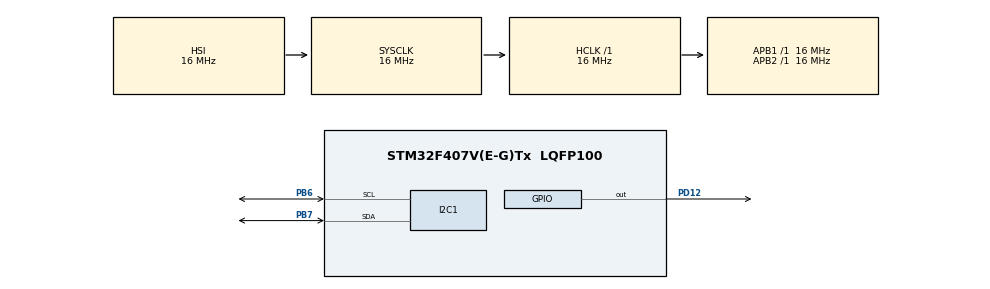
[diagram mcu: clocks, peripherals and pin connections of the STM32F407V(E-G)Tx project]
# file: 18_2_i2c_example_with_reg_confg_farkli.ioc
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I2C1.DutyCycle=I2C_DUTYCYCLE_16_9
I2C1.I2C_Mode=I2C_Fast
Mcu.Family=STM32F4
Mcu.Name=STM32F407V(E-G)Tx
Mcu.Package=LQFP100
NVIC.PriorityGroup=NVIC_PRIORITYGROUP_4
PA13.Mode=Serial_Wire
PA13.Signal=SYS_JTMS-SWDIO
PA14.Mode=Serial_Wire
PA14.Signal=SYS_JTCK-SWCLK
PB6.Mode=I2C
PB6.Signal=I2C1_SCL
PB7.Mode=I2C
PB7.Signal=I2C1_SDA
PD12.Signal=GPIO_Output
ProjectManager.HeapSize=0x200
ProjectManager.StackSize=0x400
ProjectManager.TargetToolchain=MDK-ARM V5
RCC.AHBFreq_Value=16000000
RCC.APB1Freq_Value=16000000
RCC.APB2Freq_Value=16000000
RCC.CortexFreq_Value=16000000
RCC.HSE_VALUE=25000000
RCC.HSI_VALUE=16000000
RCC.LSE_VALUE=32768
RCC.SYSCLKFreq_VALUE=16000000
RCC.VCOOutputFreq_Value=192000000
board=18_2_i2c_example_with_reg_confg_farkli

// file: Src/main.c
/**
  ******************************************************************************
  * File Name          : main.c
  * Description        : Main program body
  ******************************************************************************
  ** This notice applies to any and all portions of this file
  * that are not between comment pairs USER CODE BEGIN and
  * USER CODE END. Other portions of this file, whether
  * inserted by the user or by software development tools
  * are owned by their respective copyright owners.
  *
  * COPYRIGHT(c) 2018 STMicroelectronics
  *
  * Redistribution and use in source and binary forms, with or without modification,
  * are permitted provided that the following conditions are met:
  *   1. Redistributions of source code must retain the above copyright notice,
  *      this list of conditions and the following disclaimer.
  *   2. Redistributions in binary form must reproduce the above copyright notice,
  *      this list of conditions and the following disclaimer in the documentation
  *      and/or other materials provided with the distribution.
  *   3. Neither the name of STMicroelectronics nor the names of its contributors
  *      may be used to endorse or promote products derived from this software
  *      without specific prior written permission.
  *
  * THIS SOFTWARE IS PROVIDED BY THE COPYRIGHT HOLDERS AND CONTRIBUTORS "AS IS"
  * AND ANY EXPRESS OR IMPLIED WARRANTIES, INCLUDING, BUT NOT LIMITED TO, THE
  * IMPLIED WARRANTIES OF MERCHANTABILITY AND FITNESS FOR A PARTICULAR PURPOSE ARE
  * DISCLAIMED. IN NO EVENT SHALL THE COPYRIGHT HOLDER OR CONTRIBUTORS BE LIABLE
  * FOR ANY DIRECT, INDIRECT, INCIDENTAL, SPECIAL, EXEMPLARY, OR CONSEQUENTIAL
  * DAMAGES (INCLUDING, BUT NOT LIMITED TO, PROCUREMENT OF SUBSTITUTE GOODS OR
  * SERVICES; LOSS OF USE, DATA, OR PROFITS; OR BUSINESS INTERRUPTION) HOWEVER
  * CAUSED AND ON ANY THEORY OF LIABILITY, WHETHER IN CONTRACT, STRICT LIABILITY,
  * OR TORT (INCLUDING NEGLIGENCE OR OTHERWISE) ARISING IN ANY WAY OUT OF THE USE
  * OF THIS SOFTWARE, EVEN IF ADVISED OF THE POSSIBILITY OF SUCH DAMAGE.
  *
  ******************************************************************************
  */
#include "main.h"
#include "stm32f4xx_hal.h"
 #define mpu6050address 0xD0
 #define REG_CHIP_ID_1  0x75   // who_am_i
 #define REG_CHIP_ID_2  0x1C   // acce_config
 #define PWR_MGMT_1     0x6B
 #define ACCEL_XOUT_H   0x3B

I2C_HandleTypeDef hi2c1;

/* USER CODE BEGIN PV */
/* Private variables ---------------------------------------------------------*/

/* USER CODE END PV */

void SystemClock_Config(void);
static void MX_GPIO_Init(void);
static void MX_I2C1_Init(void);

/* USER CODE BEGIN PFP */
/* Private function prototypes -----------------------------------------------*/

/* USER CODE END PFP */
uint8_t i2cTx[3];
uint8_t i2cRx[10];
uint8_t x,y,z;

int main(void)
{

  /* MCU Configuration----------------------------------------------------------*/

  /* Reset of all peripherals, Initializes the Flash interface and the Systick. */
  HAL_Init();

  /* Configure the system clock */
  SystemClock_Config();

  /* Initialize all configured peripherals */
  MX_GPIO_Init();
  MX_I2C1_Init();

  /* USER CODE BEGIN 2 */
		if(HAL_I2C_IsDeviceReady(&hi2c1,0xD0,2,100)==HAL_OK) // cihazi test ediyoruz çalisiyormu diye.
		{
			HAL_GPIO_TogglePin(GPIOD,GPIO_PIN_12);
		}

		HAL_I2C_Mem_Read(&hi2c1,mpu6050address,REG_CHIP_ID_1,1,i2cRx,1,100); // çalisti yazmayi deneyelim :
		HAL_Delay(20);

		i2cTx[0]=0x00;
		HAL_I2C_Mem_Write(&hi2c1,mpu6050address,PWR_MGMT_1,1,&i2cTx[0],1,100);
		HAL_Delay(20);
	 	HAL_I2C_Mem_Read(&hi2c1,mpu6050address,PWR_MGMT_1,1,&i2cRx[1],1,100);
		HAL_Delay(20);

		i2cTx[1]=0x08;
	  HAL_I2C_Mem_Write(&hi2c1,mpu6050address,REG_CHIP_ID_2,1,&i2cTx[1],1,100);
		HAL_Delay(20);
	 	HAL_I2C_Mem_Read(&hi2c1,mpu6050address,REG_CHIP_ID_2,1,&i2cRx[2],1,100);
    HAL_Delay(20);

  /* USER CODE END 2 */

  /* Infinite loop */
  while (1)
  {
		HAL_I2C_Mem_Read(&hi2c1,mpu6050address,ACCEL_XOUT_H,1,&i2cRx[3],6,100);
    HAL_Delay(300);
  }

}

/** System Clock Configuration
*/
void SystemClock_Config(void)
{

  RCC_OscInitTypeDef RCC_OscInitStruct;
  RCC_ClkInitTypeDef RCC_ClkInitStruct;

    /**Configure the main internal regulator output voltage
    */
  __HAL_RCC_PWR_CLK_ENABLE();

  __HAL_PWR_VOLTAGESCALING_CONFIG(PWR_REGULATOR_VOLTAGE_SCALE1);

    /**Initializes the CPU, AHB and APB busses clocks
    */
  RCC_OscInitStruct.OscillatorType = RCC_OSCILLATORTYPE_HSI;
  RCC_OscInitStruct.HSIState = RCC_HSI_ON;
  RCC_OscInitStruct.HSICalibrationValue = 16;
  RCC_OscInitStruct.PLL.PLLState = RCC_PLL_NONE;
  if (HAL_RCC_OscConfig(&RCC_OscInitStruct) != HAL_OK)
  {
    _Error_Handler(__FILE__, __LINE__);
  }

    /**Initializes the CPU, AHB and APB busses clocks
    */
  RCC_ClkInitStruct.ClockType = RCC_CLOCKTYPE_HCLK|RCC_CLOCKTYPE_SYSCLK
                              |RCC_CLOCKTYPE_PCLK1|RCC_CLOCKTYPE_PCLK2;
  RCC_ClkInitStruct.SYSCLKSource = RCC_SYSCLKSOURCE_HSI;
  RCC_ClkInitStruct.AHBCLKDivider = RCC_SYSCLK_DIV1;
  RCC_ClkInitStruct.APB1CLKDivider = RCC_HCLK_DIV1;
  RCC_ClkInitStruct.APB2CLKDivider = RCC_HCLK_DIV1;

  if (HAL_RCC_ClockConfig(&RCC_ClkInitStruct, FLASH_LATENCY_0) != HAL_OK)
  {
    _Error_Handler(__FILE__, __LINE__);
  }

    /**Configure the Systick interrupt time
    */
  HAL_SYSTICK_Config(HAL_RCC_GetHCLKFreq()/1000);

    /**Configure the Systick
    */
  HAL_SYSTICK_CLKSourceConfig(SYSTICK_CLKSOURCE_HCLK);

  /* SysTick_IRQn interrupt configuration */
  HAL_NVIC_SetPriority(SysTick_IRQn, 0, 0);
}

/* I2C1 init function */
static void MX_I2C1_Init(void)
{

  hi2c1.Instance = I2C1;
  hi2c1.Init.ClockSpeed = 400000;
  hi2c1.Init.DutyCycle = I2C_DUTYCYCLE_16_9;
  hi2c1.Init.OwnAddress1 = 0;
  hi2c1.Init.AddressingMode = I2C_ADDRESSINGMODE_7BIT;
  hi2c1.Init.DualAddressMode = I2C_DUALADDRESS_DISABLE;
  hi2c1.Init.OwnAddress2 = 0;
  hi2c1.Init.GeneralCallMode = I2C_GENERALCALL_DISABLE;
  hi2c1.Init.NoStretchMode = I2C_NOSTRETCH_DISABLE;
  if (HAL_I2C_Init(&hi2c1) != HAL_OK)
  {
    _Error_Handler(__FILE__, __LINE__);
  }

}

/** Configure pins as
        * Analog
        * Input
        * Output
        * EVENT_OUT
        * EXTI
*/
static void MX_GPIO_Init(void)
{

  GPIO_InitTypeDef GPIO_InitStruct;

  /* GPIO Ports Clock Enable */
  __HAL_RCC_GPIOD_CLK_ENABLE();
  __HAL_RCC_GPIOA_CLK_ENABLE();
  __HAL_RCC_GPIOB_CLK_ENABLE();

  /*Configure GPIO pin Output Level */
  HAL_GPIO_WritePin(GPIOD, GPIO_PIN_12, GPIO_PIN_RESET);

  /*Configure GPIO pin : PD12 */
  GPIO_InitStruct.Pin = GPIO_PIN_12;
  GPIO_InitStruct.Mode = GPIO_MODE_OUTPUT_PP;
  GPIO_InitStruct.Pull = GPIO_NOPULL;
  GPIO_InitStruct.Speed = GPIO_SPEED_FREQ_LOW;
  HAL_GPIO_Init(GPIOD, &GPIO_InitStruct);

}

void _Error_Handler(char * file, int line)
{
  while(1)
  {
  }
}

/************************ (C) COPYRIGHT STMicroelectronics *****END OF FILE****/
